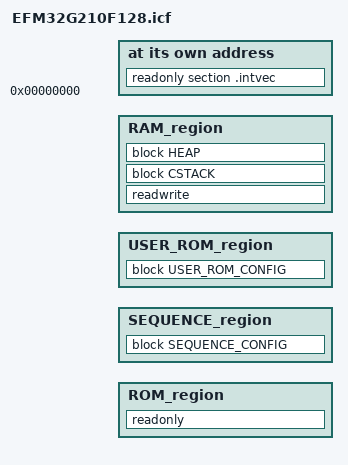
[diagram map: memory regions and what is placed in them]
/*###ICF### Section handled by ICF editor, don't touch! ****/
/*-Editor annotation file-*/
/* IcfEditorFile="$TOOLKIT_DIR$\config\ide\IcfEditor\cortex_v1_0.xml" */
/*-Specials-*/
define symbol __ICFEDIT_intvec_start__ = 0x00000000;
/*-Memory Regions-*/
define symbol __ICFEDIT_region_ROM_start__   = 0x00000000;
define symbol __ICFEDIT_region_ROM_end__     = (0x00000000+0x0001FC00-1);
define symbol __ICFEDIT_region_SEQUENCE_start__   = 0x0001FC00;
define symbol __ICFEDIT_region_SEQUENCE_end__     = (0x0001FC00+0x00000200-1);
define symbol __ICFEDIT_region_USER_ROM_start__   = 0x0001FE00;
define symbol __ICFEDIT_region_USER_ROM_end__     = (0x0001FE00+0x00000200-1);
define symbol __ICFEDIT_region_RAM_start__   = 0x20000000;
define symbol __ICFEDIT_region_RAM_end__     = (0x20000000+0x00004000-1);
/*-Sizes-*/
define symbol __ICFEDIT_size_cstack__   = 0x400;
define symbol __ICFEDIT_size_heap__     = 0x800;
define symbol __ICFEDIT_size_sequence__ = 0x200;
define symbol __ICFEDIT_size_user_rom__ = 0x200;
/**** End of ICF editor section. ###ICF###*/

define memory mem with size = 4G;
define region ROM_region   = mem:[from __ICFEDIT_region_ROM_start__   to __ICFEDIT_region_ROM_end__];
define region SEQUENCE_region   = mem:[from __ICFEDIT_region_SEQUENCE_start__   to __ICFEDIT_region_SEQUENCE_end__];
define region USER_ROM_region   = mem:[from __ICFEDIT_region_USER_ROM_start__   to __ICFEDIT_region_USER_ROM_end__];
define region RAM_region   = mem:[from __ICFEDIT_region_RAM_start__   to __ICFEDIT_region_RAM_end__];

define block CSTACK    with alignment = 8, size = __ICFEDIT_size_cstack__   { };
define block HEAP      with alignment = 8, size = __ICFEDIT_size_heap__     { };
define block SEQUENCE_CONFIG    with alignment = 8, size = __ICFEDIT_size_sequence__   { };
define block USER_ROM_CONFIG    with alignment = 8, size = __ICFEDIT_size_user_rom__   { };

initialize by copy { readwrite };
do not initialize  { section .noinit };

keep { section .intvec };
place at address mem:__ICFEDIT_intvec_start__ { readonly section .intvec };

place in ROM_region   { readonly };
place in SEQUENCE_region   { block SEQUENCE_CONFIG };
place in USER_ROM_region   { block USER_ROM_CONFIG };
place in RAM_region   { readwrite,
                        block CSTACK,
                        block HEAP };
